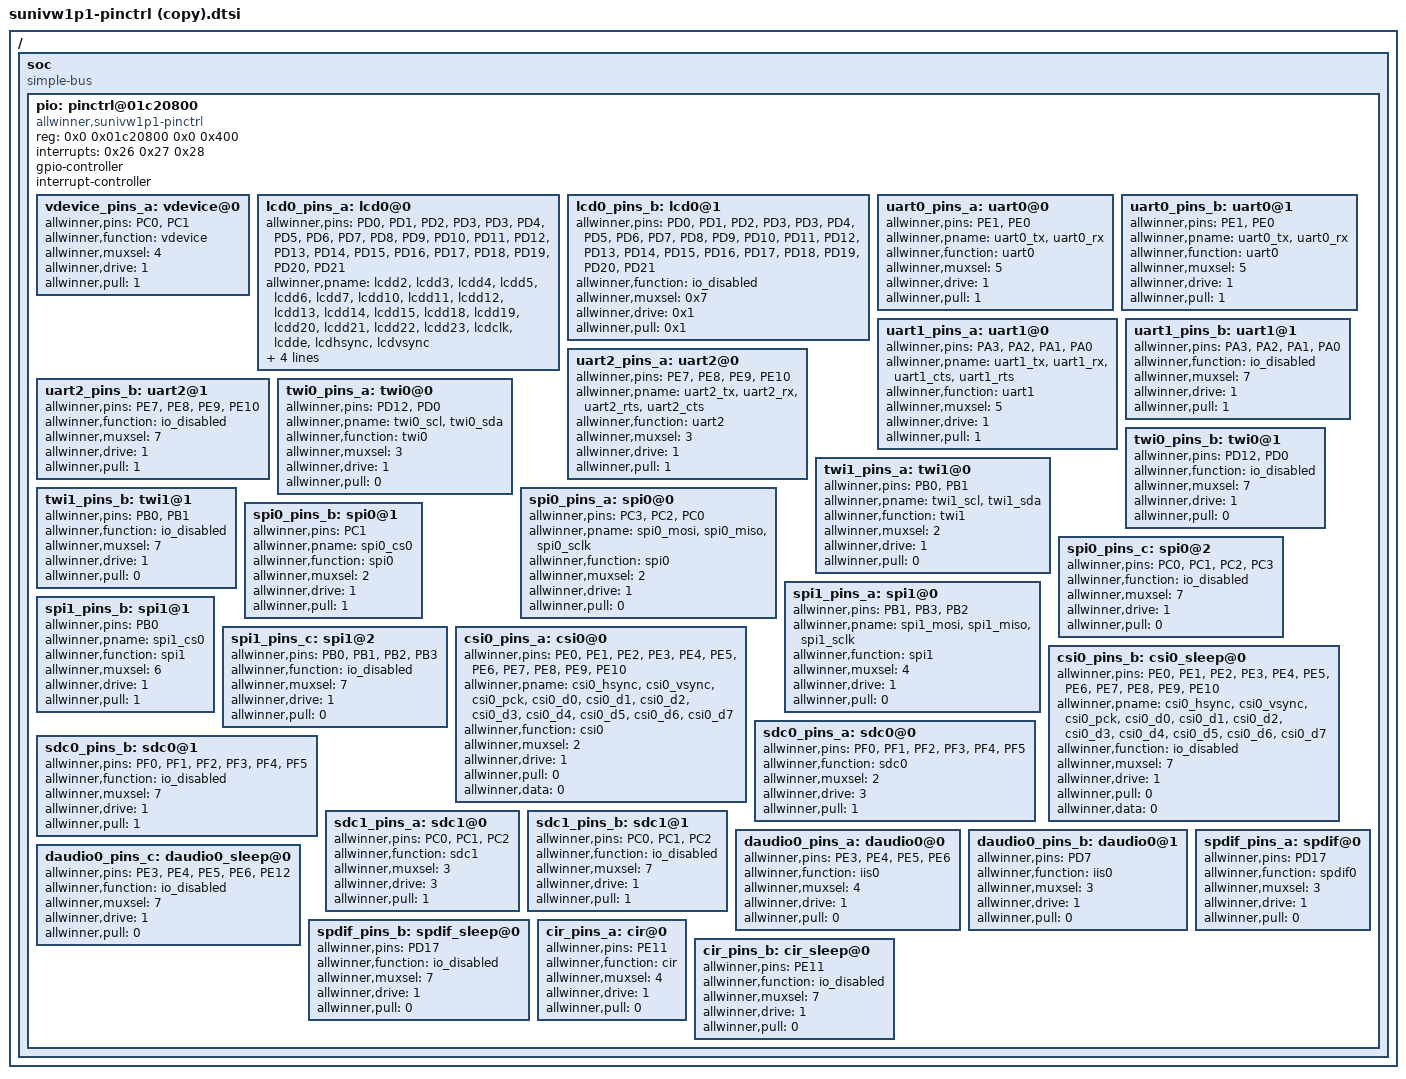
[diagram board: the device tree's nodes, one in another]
/*
 * Allwinner 1663 pin config info.
 */

/ {
	soc: soc {
		compatible = "simple-bus";
		#address-cells = <0x2>;
		#size-cells = <0x2>;
		device_type = "soc";
		ranges;

		pio: pinctrl@01c20800 {
			compatible = "allwinner,sunivw1p1-pinctrl";
			reg = <0x0 0x01c20800 0x0 0x400>;
			interrupts = <0x26 0x27 0x28>;
			device_type = "pio";
			gpio-controller;
			interrupt-controller;
			#interrupt-cells = <2>;
			#size-cells = <0>;
			#gpio-cells = <6>;

			vdevice_pins_a: vdevice@0 {
				allwinner,pins = "PC0", "PC1";
				allwinner,function = "vdevice";
				allwinner,muxsel = <4>;
				allwinner,drive = <1>;
				allwinner,pull = <1>;
			};

			lcd0_pins_a: lcd0@0 {
				allwinner,pins = "PD0", "PD1", "PD2", "PD3", "PD3", "PD4", "PD5", "PD6", "PD7", "PD8", "PD9", "PD10", "PD11", "PD12", "PD13", "PD14", "PD15", "PD16", "PD17", "PD18", "PD19", "PD20", "PD21";
				allwinner,pname = "lcdd2", "lcdd3", "lcdd4", "lcdd5", "lcdd6", "lcdd7", "lcdd10", "lcdd11", "lcdd12", "lcdd13", "lcdd14", "lcdd15", "lcdd18", "lcdd19", "lcdd20", "lcdd21", "lcdd22", "lcdd23", "lcdclk", "lcdde", "lcdhsync", "lcdvsync";
				allwinner,function = "lcd0";
				allwinner,muxsel = <0x2>;
				allwinner,drive = <0x1>;
				allwinner,pull = <0x1>;
			};

			lcd0_pins_b: lcd0@1 {
				allwinner,pins = "PD0", "PD1", "PD2", "PD3", "PD3", "PD4", "PD5", "PD6", "PD7", "PD8", "PD9", "PD10", "PD11", "PD12", "PD13", "PD14", "PD15", "PD16", "PD17", "PD18", "PD19", "PD20", "PD21";
				allwinner,function = "io_disabled";
				allwinner,muxsel = <0x7>;
				allwinner,drive = <0x1>;
				allwinner,pull = <0x1>;
			};


			uart0_pins_a: uart0@0 {
				allwinner,pins = "PE1", "PE0";
				allwinner,pname = "uart0_tx", "uart0_rx";
				allwinner,function = "uart0";
				allwinner,muxsel = <5>;
				allwinner,drive = <1>;
				allwinner,pull = <1>;
			};

			uart0_pins_b: uart0@1 {
				allwinner,pins = "PE1", "PE0";
				allwinner,pname = "uart0_tx", "uart0_rx";
				allwinner,function = "uart0";
				allwinner,muxsel = <5>;
				allwinner,drive = <1>;
				allwinner,pull = <1>;
			};

			uart1_pins_a: uart1@0 {
				allwinner,pins = "PA3", "PA2", "PA1", "PA0";
				allwinner,pname = "uart1_tx", "uart1_rx", "uart1_cts", "uart1_rts";
				allwinner,function = "uart1";
				allwinner,muxsel = <5>;
				allwinner,drive = <1>;
				allwinner,pull = <1>;
			};

			uart1_pins_b: uart1@1 {
				allwinner,pins = "PA3", "PA2", "PA1", "PA0";
				allwinner,function = "io_disabled";
				allwinner,muxsel = <7>;
				allwinner,drive = <1>;
				allwinner,pull = <1>;
			};

			uart2_pins_a: uart2@0 {
				allwinner,pins = "PE7", "PE8", "PE9", "PE10";
				allwinner,pname = "uart2_tx", "uart2_rx", "uart2_rts", "uart2_cts";
				allwinner,function = "uart2";
				allwinner,muxsel = <3>;
				allwinner,drive = <1>;
				allwinner,pull = <1>;
			};

			uart2_pins_b: uart2@1 {
				allwinner,pins = "PE7", "PE8", "PE9", "PE10";
				allwinner,function = "io_disabled";
				allwinner,muxsel = <7>;
				allwinner,drive = <1>;
				allwinner,pull = <1>;
			};

			twi0_pins_a: twi0@0 {
				allwinner,pins = "PD12", "PD0";
				allwinner,pname = "twi0_scl", "twi0_sda";
				allwinner,function = "twi0";
				allwinner,muxsel = <3>;
				allwinner,drive = <1>;
				allwinner,pull = <0>;
			};

			twi0_pins_b: twi0@1 {
				allwinner,pins = "PD12", "PD0";
				allwinner,function = "io_disabled";
				allwinner,muxsel = <7>;
				allwinner,drive = <1>;
				allwinner,pull = <0>;
			};

			twi1_pins_a: twi1@0 {
				allwinner,pins = "PB0", "PB1";
				allwinner,pname = "twi1_scl", "twi1_sda";
				allwinner,function = "twi1";
				allwinner,muxsel = <2>;
				allwinner,drive = <1>;
				allwinner,pull = <0>;
			};

			twi1_pins_b: twi1@1 {
				allwinner,pins = "PB0", "PB1";
				allwinner,function = "io_disabled";
				allwinner,muxsel = <7>;
				allwinner,drive = <1>;
				allwinner,pull = <0>;
			};

			/*twi2_pins_a: twi2@0 {
				allwinner,pins = "PE0", "PE1";
				allwinner,pname = "twi2_scl", "twi2_sda";
				allwinner,function = "twi2";
				allwinner,muxsel = <4>;
				allwinner,drive = <1>;
				allwinner,pull = <0>;
			};

			twi2_pins_b: twi2@1 {
				allwinner,pins = "PE0", "PE1";
				allwinner,function = "io_disabled";
				allwinner,muxsel = <7>;
				allwinner,drive = <1>;
				allwinner,pull = <0>;
			};*/

			spi0_pins_a: spi0@0 {
				allwinner,pins = "PC3", "PC2", "PC0";
				allwinner,pname = "spi0_mosi", "spi0_miso", "spi0_sclk";
				allwinner,function = "spi0";
				allwinner,muxsel = <2>;
				allwinner,drive = <1>;
				allwinner,pull = <0>;
			};

			spi0_pins_b: spi0@1 {
				allwinner,pins = "PC1"; 
				allwinner,pname = "spi0_cs0";
				allwinner,function = "spi0";
				allwinner,muxsel = <2>;
				allwinner,drive = <1>;
				allwinner,pull = <1>; 	// only CS should be pulled up
			};

			spi0_pins_c: spi0@2 {
				allwinner,pins = "PC0", "PC1", "PC2", "PC3"; 
				allwinner,function = "io_disabled";
				allwinner,muxsel = <7>;
				allwinner,drive = <1>;
				allwinner,pull = <0>;
			};

			spi1_pins_a: spi1@0 {
				//allwinner,pins = "PE9", "PE7", "PE8";
				//allwinner,pname = "spi1_sclk", "spi1_cs0", "spi1_mosi";
				allwinner,pins = "PB1", "PB3", "PB2";
				allwinner,pname = "spi1_mosi", "spi1_miso", "spi1_sclk";
				allwinner,function = "spi1";
				allwinner,muxsel = <4>;
				allwinner,drive = <1>;
				allwinner,pull = <0>;
			};

			spi1_pins_b: spi1@1 {
				allwinner,pins = "PB0";
				allwinner,pname = "spi1_cs0";
				allwinner,function = "spi1";
				allwinner,muxsel = <6>;
				allwinner,drive = <1>;
				allwinner,pull = <1>; 	// only CS should be pulled up
			};

			spi1_pins_c: spi1@2 {
				allwinner,pins = "PB0", "PB1", "PB2", "PB3";
				allwinner,function = "io_disabled";
				allwinner,muxsel = <7>;
				allwinner,drive = <1>;
				allwinner,pull = <0>;
			};

			csi0_pins_a: csi0@0 {
				allwinner,pins = "PE0","PE1","PE2","PE3","PE4","PE5","PE6","PE7","PE8","PE9","PE10";
				allwinner,pname = "csi0_hsync","csi0_vsync","csi0_pck","csi0_d0","csi0_d1","csi0_d2",
								"csi0_d3","csi0_d4","csi0_d5","csi0_d6","csi0_d7";
				allwinner,function = "csi0";
				allwinner,muxsel = <2>;
				allwinner,drive = <1>;
				allwinner,pull = <0>;
				allwinner,data = <0>;
			};

			csi0_pins_b: csi0_sleep@0 {
				allwinner,pins = "PE0","PE1","PE2","PE3","PE4","PE5","PE6","PE7","PE8","PE9","PE10";
				allwinner,pname = "csi0_hsync","csi0_vsync","csi0_pck","csi0_d0","csi0_d1","csi0_d2",
								"csi0_d3","csi0_d4","csi0_d5","csi0_d6","csi0_d7";
				allwinner,function = "io_disabled";
				allwinner,muxsel = <7>;
				allwinner,drive = <1>;
				allwinner,pull = <0>;
				allwinner,data = <0>;
			};

			sdc0_pins_a: sdc0@0 {
				allwinner,pins = "PF0", "PF1", "PF2", "PF3","PF4","PF5";
				allwinner,function = "sdc0";
				allwinner,muxsel = <2>;
				allwinner,drive = <3>;
				allwinner,pull = <1>;
			};
			sdc0_pins_b: sdc0@1 {
				allwinner,pins = "PF0", "PF1", "PF2", "PF3", "PF4", "PF5";
				allwinner,function = "io_disabled";
				allwinner,muxsel = <7>;
				allwinner,drive = <1>;
				allwinner,pull = <1>;
			};
		
			sdc1_pins_a: sdc1@0 {
				allwinner,pins = "PC0", "PC1", "PC2";
				allwinner,function = "sdc1";
				allwinner,muxsel = <3>;
				allwinner,drive = <3>;
				allwinner,pull = <1>;
			};

			sdc1_pins_b: sdc1@1 {
				allwinner,pins = "PC0", "PC1", "PC2";
				allwinner,function = "io_disabled";
				allwinner,muxsel = <7>;
				allwinner,drive = <1>;
				allwinner,pull = <1>;
			};

			daudio0_pins_a: daudio0@0 {
				allwinner,pins = "PE3", "PE4", "PE5", "PE6";
				allwinner,function = "iis0";
				allwinner,muxsel = <4>;
				allwinner,drive = <1>;
				allwinner,pull = <0>;
			};

			daudio0_pins_b: daudio0@1 {
				allwinner,pins = "PD7";
				allwinner,function = "iis0";
				allwinner,muxsel = <3>;
				allwinner,drive = <1>;
				allwinner,pull = <0>;
			};

			daudio0_pins_c: daudio0_sleep@0 {
				allwinner,pins = "PE3", "PE4", "PE5", "PE6", "PE12";
				allwinner,function = "io_disabled";
				allwinner,muxsel = <7>;
				allwinner,drive = <1>;
				allwinner,pull = <0>;
			};

			spdif_pins_a: spdif@0 {
				allwinner,pins = "PD17";
				allwinner,function = "spdif0";
				allwinner,muxsel = <3>;
				allwinner,drive = <1>;
				allwinner,pull = <0>;
			};

			spdif_pins_b: spdif_sleep@0 {
				allwinner,pins = "PD17";
				allwinner,function = "io_disabled";
				allwinner,muxsel = <7>;
				allwinner,drive = <1>;
				allwinner,pull = <0>;
			};
			
			cir_pins_a: cir@0 {
				allwinner,pins = "PE11";
				allwinner,function = "cir";
				allwinner,muxsel = <4>;
				allwinner,drive = <1>;
				allwinner,pull = <0>;
			};
			
			cir_pins_b: cir_sleep@0 {
				allwinner,pins = "PE11";
				allwinner,function = "io_disabled";
				allwinner,muxsel = <7>;
				allwinner,drive = <1>;
				allwinner,pull = <0>;
			};

		};
	};
};
